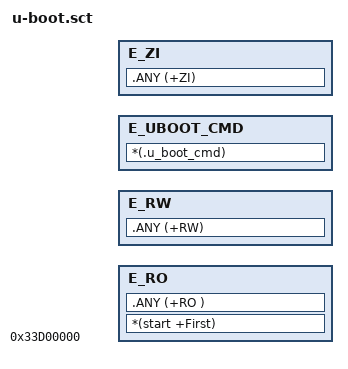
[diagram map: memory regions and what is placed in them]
; * ----------------------------------------------------------------------------
; *         Linker scatter for running in external SDRAM on the TQ2440 board
; * ----------------------------------------------------------------------------
; * Copyright (c) 2008, luoqindong
; *
; * All rights reserved.
; *
; * Redistribution and use in source and binary forms, with or without
; * modification, are permitted provided that the following conditions are met:
; *
; * - Redistributions of source code must retain the above copyright notice,
; * this list of conditions and the disclaimer below.
; *
; * DISCLAIMER: THIS SOFTWARE IS PROVIDED BY ATMEL "AS IS" AND ANY EXPRESS OR
; * IMPLIED WARRANTIES, INCLUDING, BUT NOT LIMITED TO, THE IMPLIED WARRANTIES OF
; * MERCHANTABILITY, FITNESS FOR A PARTICULAR PURPOSE AND NON-INFRINGEMENT ARE
; * DISCLAIMED. IN NO EVENT SHALL ATMEL BE LIABLE FOR ANY DIRECT, INDIRECT,
; * INCIDENTAL, SPECIAL, EXEMPLARY, OR CONSEQUENTIAL DAMAGES (INCLUDING, BUT NOT
; * LIMITED TO, PROCUREMENT OF SUBSTITUTE GOODS OR SERVICES; LOSS OF USE, DATA,
; * OR PROFITS; OR BUSINESS INTERRUPTION) HOWEVER CAUSED AND ON ANY THEORY OF
; * LIABILITY, WHETHER IN CONTRACT, STRICT LIABILITY, OR TORT (INCLUDING
; * NEGLIGENCE OR OTHERWISE) ARISING IN ANY WAY OUT OF THE USE OF THIS SOFTWARE,
; * EVEN IF ADVISED OF THE POSSIBILITY OF SUCH DAMAGE.
; * ----------------------------------------------------------------------------

; *------------------------------------------------------------------------------
; *      Linker scatter for running in external SDRAM on the TQ2440 board
; *----------------------------------------------------------------------------*/

Load_region 0x33d00000 {

    E_RO 0x33d00000 {
		*(start +First)
        .ANY (+RO )
    }
	E_RW +0 {
		.ANY (+RW)
	}
				 
	E_UBOOT_CMD  +0 {
		*(.u_boot_cmd)
	}
	 
	E_ZI +0{
		.ANY (+ZI)
	}
}
; Check uncompressed size of LoadRegion
;ScatterAssert(ImageLength(Load_region) < (SDRAM_END_ADDRESS - START_ADDRESS)) 

